# RTS591x register map
Vendor: Realtek Semiconductor Corp.; Series: RTS591x Series; File version: 1.0
CPU: ARMV8MML r0p0, little endian, MPU, FPU, VTOR, 3 interrupt priority bits, 4 SAU regions
Registers are 32-bit, read-write, reset 0x0 unless marked. A register's access mark holds for its fields unless they carry their own. Offsets are from the block's base; [hi:lo] are bit positions; {n}, {i} and the like mark numbered series.

## SLWTMR0 — 32-bit SlowTimer Controller
Base 0x4000C200
Same registers: SLWTMR1 0x4000C210, RTMR 0x4000C500
0x00 LDCNT — LOAD COUNTER REGISTER
0x04 CNT — CURRENT COUNTER REGISTER
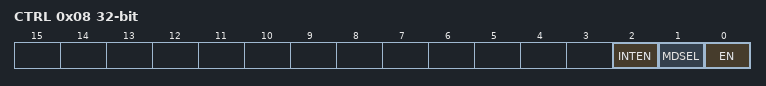
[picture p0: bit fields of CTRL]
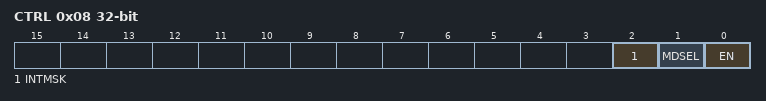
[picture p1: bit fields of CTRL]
0x08 CTRL — CONTROL REGISTER
  [2] INTEN — Enable Timer Interrupt
    0=DISABLE (Disable timer interrupt); 1=ENABLE (Enable timer interrupt)
  [1] MDSEL — Timer Operating Mode Selection
    0=ONE_SHOT (Timer is operate at one-shot mode); 1=CONTINUOUS (Timer is operate at continuous mode)
  [0] EN — Enable Timer Contoller
    0=DISABLE (Disable timer controller); 1=ENABLE (Enable timer controller)
0x0C INTSTS — INTERRUPT STATUS REGISTER
  [0] STS write-1-clears — Timer Interrupt Status
    0=NOT_OCCURRED (Timer interrupt is not occurred); 1=OCCURRED (Timer interrupt is occurred)

## TMR0 — 32-bit Timer Controller
Base 0x4000C300
Same registers: TMR1 0x4000C314, TMR2 0x4000C328, TMR3 0x4000C33C, TMR4 0x4000C350, TMR5 0x4000C364
0x00 LDCNT — LOAD COUNTER REGISTER
0x04 CNT — CURRENT COUNTER REGISTER
0x08 CTRL — CONTROL REGISTER
  [2] INTMSK — Timer Interrupt Mask
    0=NOT_MASK (Timer interrupt is not masked (Enable)); 1=MASK (Timer interrupt is masked (Disable))
  [1] MDSEL — Timer Operating Mode Selection
    0=FREE_RUN (Timer is operate at free-run mode); 1=USER_DEFINED (Timer is operate at user-defined mode)
  [0] EN — Enable Timer Contoller
    0=DISABLE (Disable timer controller); 1=ENABLE (Enable timer controller)
0x0C INTCLR ro — INTERRUPT CLEAR REGISTER
0x10 INTSTS ro — INTERRUPT STATUS REGISTER
  [0] STS — Timer Interrupt Status
    0=NOT_OCCURRED (Timer interrupt is not occurred); 1=OCCURRED (Timer interrupt is occurred)

## PWM0 — PWM Controller
Base 0x4000F000
Same registers: PWM{n} {0x4000F000+0xC*n} (n=1..11)
0x00 DUTY — PWM DUTY REGISTER
0x04 DIV — PWM DIVIDER REGISTER
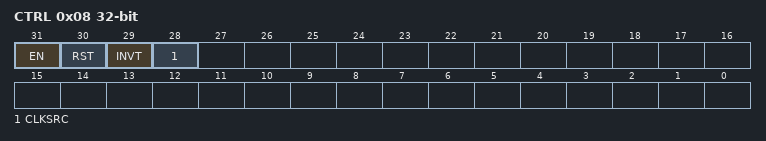
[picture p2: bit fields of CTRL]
0x08 CTRL — PWM CONTROL REGISTER
  [31] EN — Enable PWM Controller
    0=DISABLE (Disable PWM Controller); 1=ENABLE (Enable PWM Controller)
  [30] RST — Reset PWM Controller
    0=DO_NOTHING; 1=RESET (Reset PWM controller)
  [29] INVT — Output Inverter Control
    0=NORMAL (PWM output is not invert); 1=INVERT (PWM output is invert)
  [28] CLKSRC — Clock Source Selection
    0=PLL (PWM clock source is from PLL); 1=RC32K (PWM clock source is from RC32K)

## PWMLED0 — PWMLED Controller
Base 0x4000F800
Same registers: PWMLED1 0x4000F818
0x00 MODE
  [1:0] SEL — Mode Selection
    0=OFF (PWMLED ouput is off); 1=BREATHING (PWMLED is under breathing mode); 2=BLINKING (PWMLED is under blinking mode); 3=ALWAYS_ON (PWMLED ouput is always on)
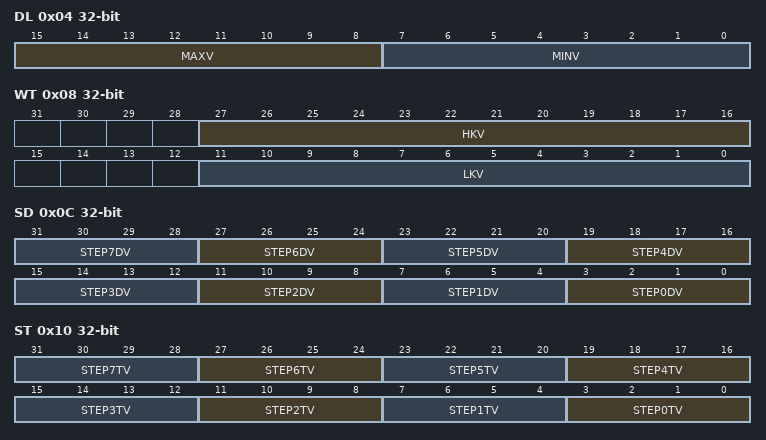
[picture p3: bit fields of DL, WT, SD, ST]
0x04 DL — DUTY LIMIT REGISTER
  [15:8] MAXV — Maximum Duty Cycle
  [7:0] MINV — Minimum Duty Cycle
0x08 WT — WAIT TIME REGISTER
  [27:16] HKV — High wait-time
  [11:0] LKV — Low wait-time
0x0C SD — STEP DUTY REGISTER
  [4n+3:4n] STEP{n}DV (n=0..7) — Step{n} Duty Value
0x10 ST — STEP TIME REGISTER
  [4n+3:4n] STEP{n}TV (n=0..7) — Step{n} Time Value
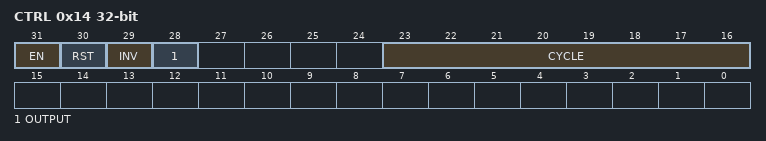
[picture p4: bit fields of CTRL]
0x14 CTRL — CONTROL REGISTER
  [31] EN — Enable PWMLED Controller
    0=DISABLE (Disable PWMLED Controller); 1=ENABLE (Enable PWMLED Controller)
  [30] RST — Reset PWM LED Controller
    0=DO_NOTHING; 1=RESET (Reset PWM LED controller)
  [29] INV — Output Inverter Control
    0=NORMAL (PWM output is not invert); 1=INVERT (PWM output is invert)
  [28] OUTPUT — Control the output method
    0=ALWAYS_ON (Output is always on); 1=BY_CYCLE (Output is stop when entire cycle is finished)
  [23:16] CYCLE — The number of output cycle

## TACHO0 — Tachometer Controller
Base 0x4000FD00
Same registers: TACHO1 0x4000FD40, TACHO2 0x4000FD80, TACHO3 0x4000FDC0
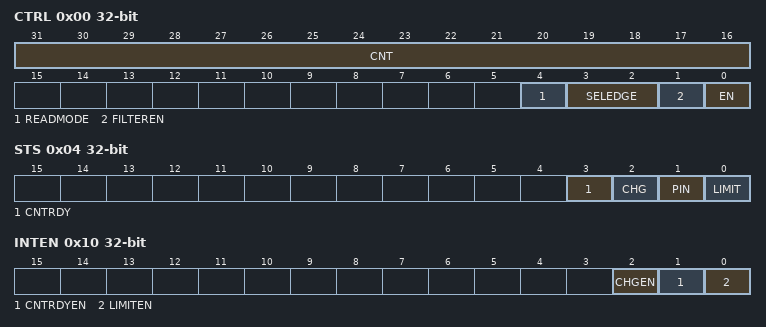
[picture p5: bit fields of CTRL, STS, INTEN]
0x00 CTRL — CONTROL REGISTER
  [31:16] CNT ro — Counter of Tachometer
  [4] READMODE — Select Reading Mode of Tachometer
    0=LOW_TO_HIGH (Counter is incremented when input transitions from low-to-high); 1=RISING_EDGE (Counter is incremented on the rising edge of the 100KHz input)
  [3:2] SELEDGE — Select Edges of Tachometer
    0=x2 (x2 edges (1/2 TACH period)); 1=x3 (x3 edges (1/2 TACH period)); 2=x5 (x5 edges (2 TACH period)); 3=x9 (x9 edges (4 TACH period))
  [1] FILTEREN — Enable Filter of Tachometer
    0=DISABLE (Disabled TACH filter); 1=ENABLE (Enabled TACH filter)
  [0] EN — Enable Tachometer Controller
    0=DISABLE (Disable tachometer controller); 1=ENABLE (Enabled tachometer controller)
0x04 STS — STATUS REGISTER
  [3] CNTRDY — Status of Count Ready
    0=NOT_READY (Tachometer is not ready to count); 1=READY (Tachometer is ready to count)
  [2] CHG — Tachometer Input Changes Its Status
    0=STABLE (Tachometer input status is stable); 1=CHANGED (Tachometer input status is changed)
  [1] PIN ro — Pin Status of Tachometer
    0=LOW (Tachometer input pin is low); 1=HIGH (Tachometer input pin is high)
  [0] LIMIT — Limit status of Tachometer
    0=WITHIN (Counter is within limit); 1=OUTSIDE (Counter is outside of limit)
0x08 LIMITH — HIGH-LIMIT REGISTER
  [15:0] VAL — High limit value
0x0C LIMITL — LOW-LIMIT REGISTER
  [15:0] VAL — Low limit value
0x10 INTEN — INTERRUPT ENABLE REGISTER
  [2] CHGEN — Input Change Interrupt Enable
    0=DISABLE (Disabled input change interrupt); 1=ENABLE (Enabled input change interrupt)
  [1] CNTRDYEN — Ready to count Interrupt Enable
    0=DISABLE (Disabled ready to count interrupt); 1=ENABLE (Enabled ready to count interrupt)
  [0] LIMITEN — Limit Interrupt Enable
    0=DISABLE (Disabled limit interrupt); 1=ENABLE (Enabled limit interrupt)
